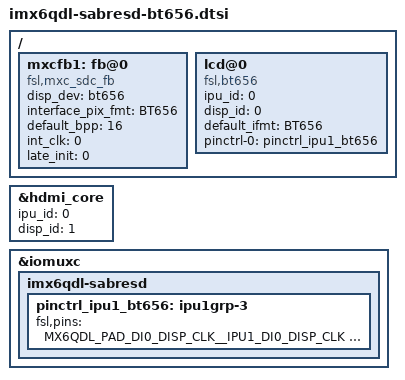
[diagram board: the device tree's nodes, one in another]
/*
 * Copyright (C) 2016 Freescale Semiconductor, Inc.
 *
 * This program is free software; you can redistribute it and/or modify
 * it under the terms of the GNU General Public License version 2 as
 * published by the Free Software Foundation.
 */

/ {
	mxcfb1: fb@0 {
		compatible = "fsl,mxc_sdc_fb";
		disp_dev = "bt656";
		interface_pix_fmt = "BT656";
		default_bpp = <16>;
		int_clk = <0>;
		late_init = <0>;
		status = "okay";
	};

	lcd@0 {
		compatible = "fsl,bt656";
		ipu_id = <0>;
		disp_id = <0>;
		default_ifmt = "BT656";
		pinctrl-names = "default";
		pinctrl-0 = <&pinctrl_ipu1_bt656>;
		status = "okay";
	};
};

&hdmi_core {
	ipu_id = <0>;
	disp_id = <1>;
	status = "okay";
};

&iomuxc {
	imx6qdl-sabresd {
		pinctrl_ipu1_bt656: ipu1grp-3 {
			fsl,pins = <
				MX6QDL_PAD_DI0_DISP_CLK__IPU1_DI0_DISP_CLK 0x10
				MX6QDL_PAD_DISP0_DAT16__IPU1_DISP0_DATA16  0x10
				MX6QDL_PAD_DISP0_DAT17__IPU1_DISP0_DATA17  0x10
				MX6QDL_PAD_DISP0_DAT18__IPU1_DISP0_DATA18  0x10
				MX6QDL_PAD_DISP0_DAT19__IPU1_DISP0_DATA19  0x10
				MX6QDL_PAD_DISP0_DAT20__IPU1_DISP0_DATA20  0x10
				MX6QDL_PAD_DISP0_DAT21__IPU1_DISP0_DATA21  0x10
				MX6QDL_PAD_DISP0_DAT22__IPU1_DISP0_DATA22  0x10
				MX6QDL_PAD_DISP0_DAT23__IPU1_DISP0_DATA23  0x10
			>;
		};
	};
};

